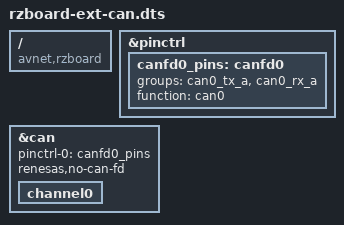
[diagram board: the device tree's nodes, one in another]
/*
 * Copyright 2021 AVNET
 *
 * This program is free software; you can redistribute it and/or
 * modify it under the terms of the GNU General Public License
 * as published by the Free Software Foundation; either version 2
 * of the License, or (at your option) any later version.
 *
 * This program is distributed in the hope that it will be useful,
 * but WITHOUT ANY WARRANTY; without even the implied warranty of
 * MERCHANTABILITY or FITNESS FOR A PARTICULAR PURPOSE.  See the
 * GNU General Public License for more details.
 */

/dts-v1/;
/plugin/;

#include <dt-bindings/pinctrl/pinctrl-rzg2l.h>

/* 40-pin extended GPIO, expanded into UART, SPI, I2C, PWM and other interfaces */

/ {
	compatible = "avnet,rzboard", "renesas,r9a07g054l2";

	fragment@0 {
		target = <&pinctrl>;
			__overlay__ {
			canfd0_pins: canfd0 {
				groups = "can0_tx_a", "can0_rx_a";
				function = "can0";
			};
		};
	};

	fragment@1 {
		target = <&can>;
		__overlay__ {
			pinctrl-0 = <&canfd0_pins>;
			pinctrl-names = "default";
			status = "okay";

			/* Default set as Classical CAN(CAN 2.0) mode, remove to enable CAN FD mode */
			renesas,no-can-fd;

			channel0 {
				status = "okay";
			};
		};
	};
};
